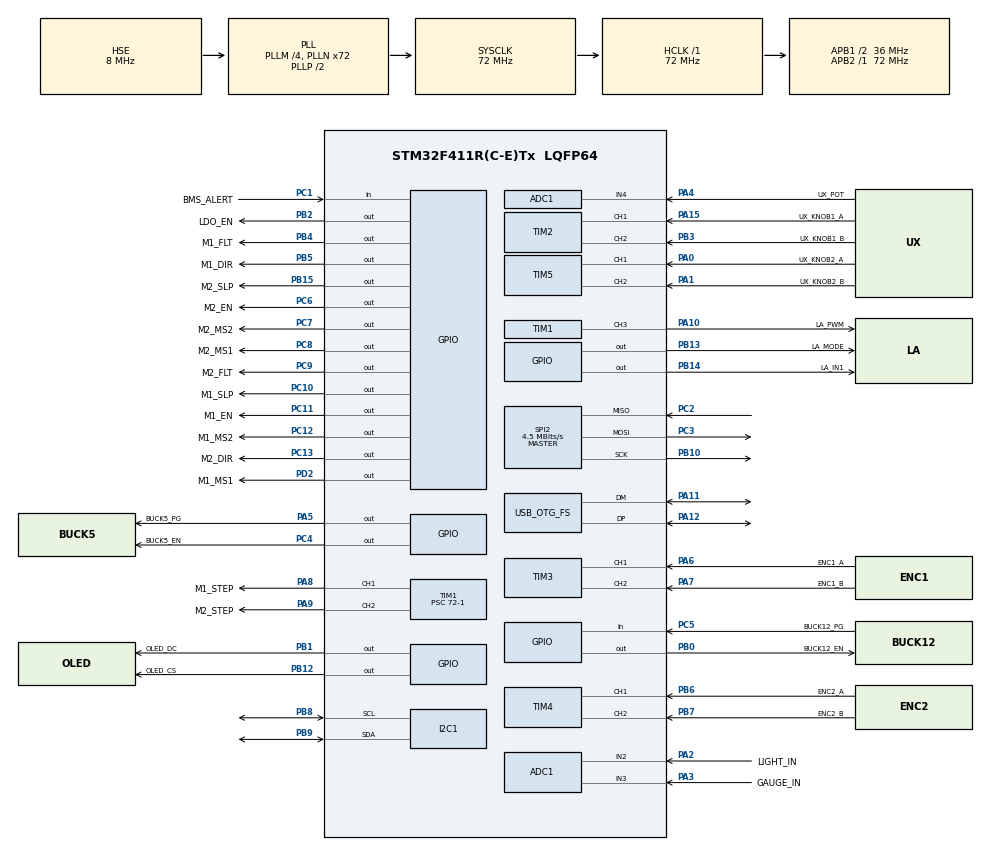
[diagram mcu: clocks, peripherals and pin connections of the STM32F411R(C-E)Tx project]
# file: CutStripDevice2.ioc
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ADC1.Channel-0\#ChannelRegularConversion=ADC_CHANNEL_3
ADC1.NbrOfConversionFlag=1
ADC1.Rank-0\#ChannelRegularConversion=1
ADC1.SamplingTime-0\#ChannelRegularConversion=ADC_SAMPLETIME_3CYCLES
ADC1.master=1
FREERTOS.Tasks01=idle,8,128,StartDefaultTask,Default,NULL,Dynamic,NULL,NULL
FREERTOS.configCHECK_FOR_STACK_OVERFLOW=2
FREERTOS.configGENERATE_RUN_TIME_STATS=1
FREERTOS.configUSE_MALLOC_FAILED_HOOK=1
FREERTOS.configUSE_NEWLIB_REENTRANT=1
FREERTOS.configUSE_STATS_FORMATTING_FUNCTIONS=1
I2C1.OwnAddress=0x08
Mcu.Family=STM32F4
Mcu.Name=STM32F411R(C-E)Tx
Mcu.Package=LQFP64
NVIC.OTG_FS_IRQn=true\:5\:0\:false\:false\:true\:true\:false\:true\:true
NVIC.PriorityGroup=NVIC_PRIORITYGROUP_4
NVIC.TIM1_BRK_TIM9_IRQn=true\:15\:0\:false\:false\:true\:false\:false\:true\:true
NVIC.TimeBase=TIM1_BRK_TIM9_IRQn
NVIC.TimeBaseIP=TIM9
PA0-WKUP.GPIO_Label=UX_KNOB2_A
PA0-WKUP.Signal=S_TIM5_CH1
PA1.GPIO_Label=UX_KNOB2_B
PA1.Signal=S_TIM5_CH2
PA10.GPIO_Label=LA_PWM
PA10.Signal=S_TIM1_CH3
PA11.Mode=Device_Only
PA11.Signal=USB_OTG_FS_DM
PA12.Mode=Device_Only
PA12.Signal=USB_OTG_FS_DP
PA13.GPIO_Label=TMS
PA13.Signal=SYS_JTMS-SWDIO
PA14.GPIO_Label=TCK
PA14.Signal=SYS_JTCK-SWCLK
PA15.GPIO_Label=UX_KNOB1_A
PA15.Signal=S_TIM2_CH1_ETR
PA2.GPIO_Label=LIGHT_IN
PA2.Signal=ADCx_IN2
PA3.GPIO_Label=GAUGE_IN
PA3.Signal=ADCx_IN3
PA4.GPIO_Label=UX_POT
PA4.Signal=ADCx_IN4
PA5.GPIO_Label=BUCK5_PG
PA5.Signal=GPIO_Output
PA6.GPIO_Label=ENC1_A
PA6.Signal=S_TIM3_CH1
PA7.GPIO_Label=ENC1_B
PA7.Signal=S_TIM3_CH2
PA8.GPIO_Label=M1_STEP
PA8.Signal=S_TIM1_CH1
PA9.GPIO_Label=M2_STEP
PA9.Signal=S_TIM1_CH2
PB0.GPIO_Label=BUCK12_EN
PB0.Signal=GPIO_Output
PB1.GPIO_Label=OLED_DC
PB1.Signal=GPIO_Output
PB10.GPIO_PuPd=GPIO_NOPULL
PB10.GPIO_Speed=GPIO_SPEED_FREQ_VERY_HIGH
PB10.Mode=Full_Duplex_Master
PB10.Signal=SPI2_SCK
PB12.GPIO_Label=OLED_CS
PB12.PinState=GPIO_PIN_SET
PB12.Signal=GPIO_Output
PB13.GPIO_Label=LA_MODE
PB13.Signal=GPIO_Output
PB14.GPIO_Label=LA_IN1
PB14.Signal=GPIO_Output
PB15.GPIO_Label=M2_SLP
PB15.Signal=GPIO_Output
PB2.GPIO_Label=LDO_EN
PB2.Signal=GPIO_Output
PB3.GPIO_Label=UX_KNOB1_B
PB3.Signal=S_TIM2_CH2
PB4.GPIO_Label=M1_FLT
PB4.Signal=GPIO_Output
PB5.GPIO_Label=M1_DIR
PB5.Signal=GPIO_Output
PB6.GPIO_Label=ENC2_A
PB6.Signal=S_TIM4_CH1
PB7.GPIO_Label=ENC2_B
PB7.Signal=S_TIM4_CH2
PB8.Mode=I2C
PB8.Signal=I2C1_SCL
PB9.Mode=I2C
PB9.Signal=I2C1_SDA
PC1.GPIO_Label=BMS_ALERT
PC1.Signal=GPIO_Input
PC10.GPIO_Label=M1_SLP
PC10.Signal=GPIO_Output
PC11.GPIO_Label=M1_EN
PC11.Signal=GPIO_Output
PC12.GPIO_Label=M1_MS2
PC12.Signal=GPIO_Output
PC13-ANTI_TAMP.GPIO_Label=M2_DIR
PC13-ANTI_TAMP.Signal=GPIO_Output
PC2.GPIO_PuPd=GPIO_PULLDOWN
PC2.Mode=Full_Duplex_Master
PC2.Signal=SPI2_MISO
PC3.Mode=Full_Duplex_Master
PC3.Signal=SPI2_MOSI
PC4.GPIO_Label=BUCK5_EN
PC4.Signal=GPIO_Output
PC5.GPIO_Label=BUCK12_PG
PC5.Signal=GPIO_Input
PC6.GPIO_Label=M2_EN
PC6.Signal=GPIO_Output
PC7.GPIO_Label=M2_MS2
PC7.Signal=GPIO_Output
PC8.GPIO_Label=M2_MS1
PC8.Signal=GPIO_Output
PC9.GPIO_Label=M2_FLT
PC9.Signal=GPIO_Output
PD2.GPIO_Label=M1_MS1
PD2.Signal=GPIO_Output
PH0\ -\ OSC_IN.Mode=HSE-External-Clock-Source
PH0\ -\ OSC_IN.Signal=RCC_OSC_IN
PH1\ -\ OSC_OUT.Mode=HSE-External-Clock-Source
PH1\ -\ OSC_OUT.Signal=RCC_OSC_OUT
ProjectManager.HeapSize=0x200
ProjectManager.StackSize=0x400
ProjectManager.TargetToolchain=STM32CubeIDE
RCC.48MHZClocksFreq_Value=48000000
RCC.AHBFreq_Value=72000000
RCC.APB1CLKDivider=RCC_HCLK_DIV2
RCC.APB1Freq_Value=36000000
RCC.APB1TimFreq_Value=72000000
RCC.APB2Freq_Value=72000000
RCC.APB2TimFreq_Value=72000000
RCC.CortexFreq_Value=72000000
RCC.FLatency-AdvancedSettings=FLASH_LATENCY_2
RCC.HCLKFreq_Value=72000000
RCC.HSE_VALUE=8000000
RCC.HSI_VALUE=16000000
RCC.PLLM=4
RCC.PLLN=72
RCC.PLLQ=3
RCC.SYSCLKFreq_VALUE=72000000
RCC.SYSCLKSource=RCC_SYSCLKSOURCE_PLLCLK
RCC.VCOOutputFreq_Value=144000000
SH.ADCx_IN2.0=ADC1_IN2,IN2
SH.ADCx_IN3.0=ADC1_IN3,IN3
SH.ADCx_IN4.0=ADC1_IN4,IN4
SH.S_TIM1_CH1.0=TIM1_CH1,PWM Generation1 CH1
SH.S_TIM1_CH2.0=TIM1_CH2,PWM Generation2 CH2
SH.S_TIM1_CH3.0=TIM1_CH3,PWM Generation3 CH3
SH.S_TIM2_CH1_ETR.0=TIM2_CH1,Encoder_Interface
SH.S_TIM2_CH2.0=TIM2_CH2,Encoder_Interface
SH.S_TIM3_CH1.0=TIM3_CH1,Encoder_Interface
SH.S_TIM3_CH2.0=TIM3_CH2,Encoder_Interface
SH.S_TIM4_CH1.0=TIM4_CH1,Encoder_Interface
SH.S_TIM4_CH2.0=TIM4_CH2,Encoder_Interface
SH.S_TIM5_CH1.0=TIM5_CH1,Encoder_Interface
SH.S_TIM5_CH2.0=TIM5_CH2,Encoder_Interface
SPI2.BaudRatePrescaler=SPI_BAUDRATEPRESCALER_8
SPI2.CLKPhase=SPI_PHASE_2EDGE
SPI2.CLKPolarity=SPI_POLARITY_HIGH
SPI2.CalculateBaudRate=4.5 MBits/s
SPI2.Direction=SPI_DIRECTION_2LINES
SPI2.Mode=SPI_MODE_MASTER
SPI2.VirtualType=VM_MASTER
TIM1.Channel-PWM\ Generation1\ CH1=TIM_CHANNEL_1
TIM1.Channel-PWM\ Generation2\ CH2=TIM_CHANNEL_2
TIM1.Channel-PWM\ Generation3\ CH3=TIM_CHANNEL_3
TIM1.Prescaler=72-1
TIM1.Pulse-PWM\ Generation1\ CH1=30000
TIM1.Pulse-PWM\ Generation2\ CH2=30000
TIM1.Pulse-PWM\ Generation3\ CH3=30000
TIM3.EncoderMode=TIM_ENCODERMODE_TI12
TIM3.IC1Filter=10
TIM3.IC1Polarity=TIM_ICPOLARITY_FALLING
USB_DEVICE.CLASS_NAME_FS=CDC
USB_DEVICE.USBD_DEBUG_LEVEL=2
USB_DEVICE.VirtualMode=Cdc
USB_DEVICE.VirtualModeFS=Cdc_FS
USB_OTG_FS.VirtualMode=Device_Only
VP_FREERTOS_VS_CMSIS_V2.Mode=CMSIS_V2
VP_SYS_VS_tim9.Mode=TIM9
VP_TIM1_VS_ClockSourceINT.Mode=Internal
VP_USB_DEVICE_VS_USB_DEVICE_CDC_FS.Mode=CDC_FS
board=NUCLEO-F411RE

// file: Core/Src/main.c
/* USER CODE BEGIN Header */
/**
  ******************************************************************************
  * @file           : main.c
  * @brief          : Main program body
  ******************************************************************************
  * @attention
  *
  * Copyright (c) 2025 STMicroelectronics.
  * All rights reserved.
  *
  * This software is licensed under terms that can be found in the LICENSE file
  * in the root directory of this software component.
  * If no LICENSE file comes with this software, it is provided AS-IS.
  *
  ******************************************************************************
  */
/* USER CODE END Header */
#include "main.h"
#include "cmsis_os.h"
#include "adc.h"
#include "i2c.h"
#include "spi.h"
#include "tim.h"
#include "usb_device.h"
#include "gpio.h"

/* USER CODE BEGIN Includes */
#include <stdio.h>
#include <string.h>
#include <stdint.h>
#include <stdbool.h>
#include "math.h"
/* USER CODE END Includes */

/* USER CODE BEGIN PV */
extern USBD_HandleTypeDef hUsbDeviceFS;
/* USER CODE END PV */

void SystemClock_Config(void);
void MX_FREERTOS_Init(void);

/* USER CODE BEGIN 0 */
// Retarget printf to UART2
#ifdef __GNUC__
/* With GCC, small printf (option LD Linker->Libraries->Small printf
   set to 'Yes') calls __io_putchar() */
//int __io_putchar(int ch)
//{
//  HAL_UART_Transmit(&huart2, (uint8_t *)&ch, 1, HAL_MAX_DELAY);
//  return ch;
//}
#endif /* __GNUC__ */
/* USER CODE END 0 */

int main(void)
{

  /* MCU Configuration--------------------------------------------------------*/

  /* Reset of all peripherals, Initializes the Flash interface and the Systick. */
  HAL_Init();

  /* Configure the system clock */
  SystemClock_Config();

  /* Initialize all configured peripherals */
  MX_GPIO_Init();
  MX_SPI2_Init();
  MX_TIM1_Init();
  MX_I2C1_Init();
  MX_ADC1_Init();
  MX_TIM3_Init();
  MX_TIM4_Init();
  MX_TIM2_Init();
  MX_TIM5_Init();
  /* USER CODE BEGIN 2 */

//  // USB INITIALIZATION
//  MX_USB_DEVICE_Init();
//  HAL_Delay(2000);
//  uint32_t timeout = HAL_GetTick() + 10000;
//  while(hUsbDeviceFS.dev_state != USBD_STATE_CONFIGURED)
//  {
//      HAL_Delay(100);
//      if(HAL_GetTick() > timeout)
//          break;  // Give up after 10 more seconds
//  }
  /* USER CODE END 2 */

  /* Init scheduler */
  osKernelInitialize();

  /* Call init function for freertos objects (in cmsis_os2.c) */
  MX_FREERTOS_Init();

  /* Start scheduler */
  osKernelStart();

  /* We should never get here as control is now taken by the scheduler */

  /* Infinite loop */
  while (1)
  {

    /* USER CODE BEGIN 3 */
	  HAL_Delay(1000);
  }
  /* USER CODE END 3 */
}

void SystemClock_Config(void)
{
  RCC_OscInitTypeDef RCC_OscInitStruct = {0};
  RCC_ClkInitTypeDef RCC_ClkInitStruct = {0};

  /** Configure the main internal regulator output voltage
  */
  __HAL_RCC_PWR_CLK_ENABLE();
  __HAL_PWR_VOLTAGESCALING_CONFIG(PWR_REGULATOR_VOLTAGE_SCALE1);

  /** Initializes the RCC Oscillators according to the specified parameters
  * in the RCC_OscInitTypeDef structure.
  */
  RCC_OscInitStruct.OscillatorType = RCC_OSCILLATORTYPE_HSE;
  RCC_OscInitStruct.HSEState = RCC_HSE_BYPASS;
  RCC_OscInitStruct.PLL.PLLState = RCC_PLL_ON;
  RCC_OscInitStruct.PLL.PLLSource = RCC_PLLSOURCE_HSE;
  RCC_OscInitStruct.PLL.PLLM = 4;
  RCC_OscInitStruct.PLL.PLLN = 72;
  RCC_OscInitStruct.PLL.PLLP = RCC_PLLP_DIV2;
  RCC_OscInitStruct.PLL.PLLQ = 3;
  if (HAL_RCC_OscConfig(&RCC_OscInitStruct) != HAL_OK)
  {
    Error_Handler();
  }

  /** Initializes the CPU, AHB and APB buses clocks
  */
  RCC_ClkInitStruct.ClockType = RCC_CLOCKTYPE_HCLK|RCC_CLOCKTYPE_SYSCLK
                              |RCC_CLOCKTYPE_PCLK1|RCC_CLOCKTYPE_PCLK2;
  RCC_ClkInitStruct.SYSCLKSource = RCC_SYSCLKSOURCE_PLLCLK;
  RCC_ClkInitStruct.AHBCLKDivider = RCC_SYSCLK_DIV1;
  RCC_ClkInitStruct.APB1CLKDivider = RCC_HCLK_DIV2;
  RCC_ClkInitStruct.APB2CLKDivider = RCC_HCLK_DIV1;

  if (HAL_RCC_ClockConfig(&RCC_ClkInitStruct, FLASH_LATENCY_2) != HAL_OK)
  {
    Error_Handler();
  }
}

void HAL_TIM_PeriodElapsedCallback(TIM_HandleTypeDef *htim)
{
  if (htim->Instance == TIM9) {
    HAL_IncTick();
  }
}

void Error_Handler(void)
{
  __disable_irq();
  while (1)
  {
  }
}
